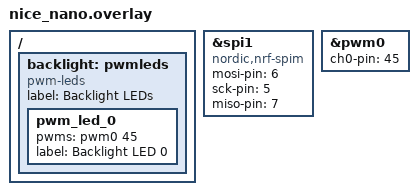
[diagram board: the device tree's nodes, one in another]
&spi1 {
	compatible = "nordic,nrf-spim";
	/* Cannot be used together with i2c0. */
	status = "okay";
	mosi-pin = <6>;
	// Unused pins, needed for SPI definition, but not used by the ws2812 driver itself.
	sck-pin = <5>;
	miso-pin = <7>;
};

&pwm0 {
    status = "okay";
    ch0-pin = <45>;
    /* ch0-inverted; */
};

/ {
    backlight: pwmleds {
        compatible = "pwm-leds";
        label = "Backlight LEDs";
        pwm_led_0 {
            pwms = <&pwm0 45>;
            label = "Backlight LED 0";
        };
    };
};
